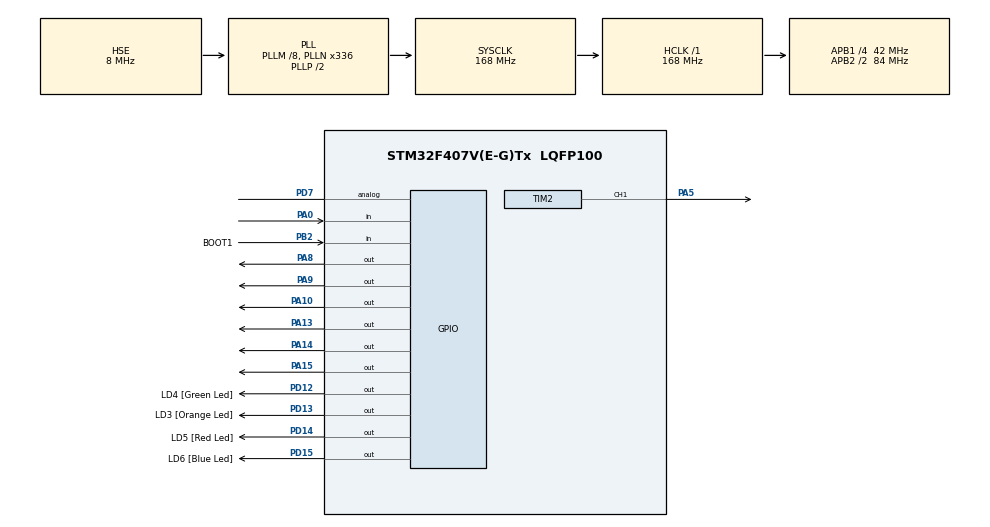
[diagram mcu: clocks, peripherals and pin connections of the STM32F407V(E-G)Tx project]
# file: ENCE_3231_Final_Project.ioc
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Mcu.Family=STM32F4
Mcu.Name=STM32F407V(E-G)Tx
Mcu.Package=LQFP100
NVIC.PriorityGroup=NVIC_PRIORITYGROUP_0
PA0-WKUP.Signal=GPIO_Input
PA10.Signal=GPIO_Output
PA13.Signal=GPIO_Output
PA14.Signal=GPIO_Output
PA15.Signal=GPIO_Output
PA5.Signal=S_TIM2_CH1_ETR
PA8.Signal=GPIO_Output
PA9.Signal=GPIO_Output
PB2.GPIO_Label=BOOT1
PB2.GPIO_Mode=GPIO_MODE_INPUT
PB2.GPIO_PuPd=GPIO_NOPULL
PB2.Signal=GPIO_Input
PC14-OSC32_IN.GPIO_Label=PC14-OSC32_IN
PC14-OSC32_IN.Mode=LSE-External-Oscillator
PC14-OSC32_IN.Signal=RCC_OSC32_IN
PC15-OSC32_OUT.GPIO_Label=PC15-OSC32_OUT
PC15-OSC32_OUT.Mode=LSE-External-Oscillator
PC15-OSC32_OUT.Signal=RCC_OSC32_OUT
PD12.GPIO_Label=LD4 [Green Led]
PD12.GPIO_PuPd=GPIO_NOPULL
PD12.GPIO_Speed=GPIO_SPEED_FREQ_LOW
PD12.Signal=GPIO_Output
PD13.GPIO_Label=LD3 [Orange Led]
PD13.GPIO_PuPd=GPIO_NOPULL
PD13.GPIO_Speed=GPIO_SPEED_FREQ_LOW
PD13.Signal=GPIO_Output
PD14.GPIO_Label=LD5 [Red Led]
PD14.GPIO_PuPd=GPIO_NOPULL
PD14.GPIO_Speed=GPIO_SPEED_FREQ_LOW
PD14.Signal=GPIO_Output
PD15.GPIO_Label=LD6 [Blue Led]
PD15.GPIO_PuPd=GPIO_NOPULL
PD15.GPIO_Speed=GPIO_SPEED_FREQ_LOW
PD15.Signal=GPIO_Output
PD7.Signal=GPIO_Analog
PE9.Signal=S_TIM1_CH1
PH0-OSC_IN.GPIO_Label=PH0-OSC_IN
PH0-OSC_IN.Mode=HSE-External-Oscillator
PH0-OSC_IN.Signal=RCC_OSC_IN
PH1-OSC_OUT.GPIO_Label=PH1-OSC_OUT
PH1-OSC_OUT.Mode=HSE-External-Oscillator
PH1-OSC_OUT.Signal=RCC_OSC_OUT
ProjectManager.HeapSize=0x200
ProjectManager.StackSize=0x400
ProjectManager.TargetToolchain=STM32CubeIDE
RCC.48MHZClocksFreq_Value=48000000
RCC.AHBFreq_Value=168000000
RCC.APB1CLKDivider=RCC_HCLK_DIV4
RCC.APB1Freq_Value=42000000
RCC.APB1TimFreq_Value=84000000
RCC.APB2CLKDivider=RCC_HCLK_DIV2
RCC.APB2Freq_Value=84000000
RCC.APB2TimFreq_Value=168000000
RCC.CortexFreq_Value=168000000
RCC.HCLKFreq_Value=168000000
RCC.HSE_VALUE=8000000
RCC.HSI_VALUE=16000000
RCC.PLLM=8
RCC.PLLN=336
RCC.PLLQ=7
RCC.PLLSourceVirtual=RCC_PLLSOURCE_HSE
RCC.SYSCLKFreq_VALUE=168000000
RCC.SYSCLKSource=RCC_SYSCLKSOURCE_PLLCLK
RCC.VCOOutputFreq_Value=336000000
SH.S_TIM1_CH1.0=TIM1_CH1
SH.S_TIM2_CH1_ETR.0=TIM2_CH1,PWM Generation1 CH1
TIM2.Channel-PWM\ Generation1\ CH1=TIM_CHANNEL_1
TIM2.Period=999
TIM2.Prescaler=71
TIM2.Pulse-PWM\ Generation1\ CH1=499
VP_TIM2_VS_ClockSourceINT.Mode=Internal
board=STM32F407G-DISC1

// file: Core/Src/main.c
/* USER CODE BEGIN Header */
/**
  ******************************************************************************
  * @file           : main.c
  * @brief          : Main program body
  ******************************************************************************
  * @attention
  *
  * Copyright (c) 2023 STMicroelectronics.
  * All rights reserved.
  *
  * This software is licensed under terms that can be found in the LICENSE file
  * in the root directory of this software component.
  * If no LICENSE file comes with this software, it is provided AS-IS.
  *
  ******************************************************************************
  */
/* USER CODE END Header */
#include "main.h"
#include <math.h>

/* USER CODE BEGIN Includes */
#include "lcd.c"
/* USER CODE END Includes */

/* USER CODE BEGIN PD */
# define PERIOD 999
# define MAXRPM 100
# define WHEELSIZE 20
/* USER CODE END PD */

TIM_HandleTypeDef htim2;

void SystemClock_Config(void);
static void MX_GPIO_Init(void);
static void MX_TIM2_Init(void);

int main(void)
{

  /* MCU Configuration--------------------------------------------------------*/

  /* Reset of all peripherals, Initializes the Flash interface and the Systick. */
  HAL_Init();

  /* Configure the system clock */
  SystemClock_Config();

  /* Initialize all configured peripherals */
  MX_GPIO_Init();
  MX_TIM2_Init();
  /* USER CODE BEGIN 2 */
  volatile int buttonFlag = 1;
  int analogValue = readAnalog();
  int convertedDC = convertDutyCycle(analogValue);
  /* Infinite loop */
  while (1)
  {
	  convertedDC = convertDutyCycle(500);
	  _HAL_TIM_SET_COMPARE(&htim2,TIM_CHANNEL_1, convertedDC);

	  if(buttonFlag = 1){
		  display("Speed", speedometer(convertedDC,WHEELSIZE));
	  }
	  if(buttonFlag = -1){
		  display("RPM", tachometer(convertedDC));
	  }

  }
}

void SystemClock_Config(void)
{
  RCC_OscInitTypeDef RCC_OscInitStruct = {0};
  RCC_ClkInitTypeDef RCC_ClkInitStruct = {0};

  /** Configure the main internal regulator output voltage
  */
  __HAL_RCC_PWR_CLK_ENABLE();
  __HAL_PWR_VOLTAGESCALING_CONFIG(PWR_REGULATOR_VOLTAGE_SCALE1);

  /** Initializes the RCC Oscillators according to the specified parameters
  * in the RCC_OscInitTypeDef structure.
  */
  RCC_OscInitStruct.OscillatorType = RCC_OSCILLATORTYPE_HSE;
  RCC_OscInitStruct.HSEState = RCC_HSE_ON;
  RCC_OscInitStruct.PLL.PLLState = RCC_PLL_ON;
  RCC_OscInitStruct.PLL.PLLSource = RCC_PLLSOURCE_HSE;
  RCC_OscInitStruct.PLL.PLLM = 8;
  RCC_OscInitStruct.PLL.PLLN = 336;
  RCC_OscInitStruct.PLL.PLLP = RCC_PLLP_DIV2;
  RCC_OscInitStruct.PLL.PLLQ = 7;
  if (HAL_RCC_OscConfig(&RCC_OscInitStruct) != HAL_OK)
  {
    Error_Handler();
  }

  /** Initializes the CPU, AHB and APB buses clocks
  */
  RCC_ClkInitStruct.ClockType = RCC_CLOCKTYPE_HCLK|RCC_CLOCKTYPE_SYSCLK
                              |RCC_CLOCKTYPE_PCLK1|RCC_CLOCKTYPE_PCLK2;
  RCC_ClkInitStruct.SYSCLKSource = RCC_SYSCLKSOURCE_PLLCLK;
  RCC_ClkInitStruct.AHBCLKDivider = RCC_SYSCLK_DIV1;
  RCC_ClkInitStruct.APB1CLKDivider = RCC_HCLK_DIV4;
  RCC_ClkInitStruct.APB2CLKDivider = RCC_HCLK_DIV2;

  if (HAL_RCC_ClockConfig(&RCC_ClkInitStruct, FLASH_LATENCY_5) != HAL_OK)
  {
    Error_Handler();
  }
}

static void MX_TIM2_Init(void)
{

  TIM_ClockConfigTypeDef sClockSourceConfig = {0};
  TIM_MasterConfigTypeDef sMasterConfig = {0};
  TIM_OC_InitTypeDef sConfigOC = {0};

  htim2.Instance = TIM2;
  htim2.Init.Prescaler = 71;
  htim2.Init.CounterMode = TIM_COUNTERMODE_UP;
  htim2.Init.Period = 999;
  htim2.Init.ClockDivision = TIM_CLOCKDIVISION_DIV1;
  htim2.Init.AutoReloadPreload = TIM_AUTORELOAD_PRELOAD_DISABLE;
  if (HAL_TIM_Base_Init(&htim2) != HAL_OK)
  {
    Error_Handler();
  }
  sClockSourceConfig.ClockSource = TIM_CLOCKSOURCE_INTERNAL;
  if (HAL_TIM_ConfigClockSource(&htim2, &sClockSourceConfig) != HAL_OK)
  {
    Error_Handler();
  }
  if (HAL_TIM_PWM_Init(&htim2) != HAL_OK)
  {
    Error_Handler();
  }
  sMasterConfig.MasterOutputTrigger = TIM_TRGO_RESET;
  sMasterConfig.MasterSlaveMode = TIM_MASTERSLAVEMODE_DISABLE;
  if (HAL_TIMEx_MasterConfigSynchronization(&htim2, &sMasterConfig) != HAL_OK)
  {
    Error_Handler();
  }
  sConfigOC.OCMode = TIM_OCMODE_PWM1;
  sConfigOC.Pulse = 499;
  sConfigOC.OCPolarity = TIM_OCPOLARITY_HIGH;
  sConfigOC.OCFastMode = TIM_OCFAST_DISABLE;
  if (HAL_TIM_PWM_ConfigChannel(&htim2, &sConfigOC, TIM_CHANNEL_1) != HAL_OK)
  {
    Error_Handler();
  }
  HAL_TIM_MspPostInit(&htim2);

}

static void MX_GPIO_Init(void)
{
  GPIO_InitTypeDef GPIO_InitStruct = {0};

  /* GPIO Ports Clock Enable */
  __HAL_RCC_GPIOC_CLK_ENABLE();
  __HAL_RCC_GPIOH_CLK_ENABLE();
  __HAL_RCC_GPIOA_CLK_ENABLE();
  __HAL_RCC_GPIOB_CLK_ENABLE();
  __HAL_RCC_GPIOE_CLK_ENABLE();
  __HAL_RCC_GPIOD_CLK_ENABLE();

  /*Configure GPIO pin Output Level */
  HAL_GPIO_WritePin(GPIOD, LD4_Pin|LD3_Pin|LD5_Pin|LD6_Pin, GPIO_PIN_RESET);

  /*Configure GPIO pin Output Level */
  HAL_GPIO_WritePin(GPIOA, GPIO_PIN_8|GPIO_PIN_9|GPIO_PIN_10|GPIO_PIN_13
                          |GPIO_PIN_14|GPIO_PIN_15, GPIO_PIN_RESET);

  /*Configure GPIO pin : B1_Pin */
  GPIO_InitStruct.Pin = B1_Pin;
  GPIO_InitStruct.Mode = GPIO_MODE_EVT_RISING;
  GPIO_InitStruct.Pull = GPIO_NOPULL;
  HAL_GPIO_Init(B1_GPIO_Port, &GPIO_InitStruct);

  /*Configure GPIO pin : BOOT1_Pin */
  GPIO_InitStruct.Pin = BOOT1_Pin;
  GPIO_InitStruct.Mode = GPIO_MODE_INPUT;
  GPIO_InitStruct.Pull = GPIO_NOPULL;
  HAL_GPIO_Init(BOOT1_GPIO_Port, &GPIO_InitStruct);

  /*Configure GPIO pin : PE9 */
  GPIO_InitStruct.Pin = GPIO_PIN_9;
  GPIO_InitStruct.Mode = GPIO_MODE_AF_PP;
  GPIO_InitStruct.Pull = GPIO_NOPULL;
  GPIO_InitStruct.Speed = GPIO_SPEED_FREQ_LOW;
  GPIO_InitStruct.Alternate = GPIO_AF1_TIM1;
  HAL_GPIO_Init(GPIOE, &GPIO_InitStruct);

  /*Configure GPIO pins : LD4_Pin LD3_Pin LD5_Pin LD6_Pin */
  GPIO_InitStruct.Pin = LD4_Pin|LD3_Pin|LD5_Pin|LD6_Pin;
  GPIO_InitStruct.Mode = GPIO_MODE_OUTPUT_PP;
  GPIO_InitStruct.Pull = GPIO_NOPULL;
  GPIO_InitStruct.Speed = GPIO_SPEED_FREQ_LOW;
  HAL_GPIO_Init(GPIOD, &GPIO_InitStruct);

  /*Configure GPIO pins : PA8 PA9 PA10 PA13
                           PA14 PA15 */
  GPIO_InitStruct.Pin = GPIO_PIN_8|GPIO_PIN_9|GPIO_PIN_10|GPIO_PIN_13
                          |GPIO_PIN_14|GPIO_PIN_15;
  GPIO_InitStruct.Mode = GPIO_MODE_OUTPUT_PP;
  GPIO_InitStruct.Pull = GPIO_NOPULL;
  GPIO_InitStruct.Speed = GPIO_SPEED_FREQ_LOW;
  HAL_GPIO_Init(GPIOA, &GPIO_InitStruct);

  /*Configure GPIO pin : PD7 */
  GPIO_InitStruct.Pin = GPIO_PIN_7;
  GPIO_InitStruct.Mode = GPIO_MODE_ANALOG;
  GPIO_InitStruct.Pull = GPIO_NOPULL;
  HAL_GPIO_Init(GPIOD, &GPIO_InitStruct);
  /* Configure GPIO pin : UserButton_Pin */
  GPIO_InitStruct.Pin = GPIO_PIN_0;
  GPIO_InitStruct.Mode = GPIO_MODE_INPUT;
  GPIO_InitStruct.Pull = GPIO_NOPULL;
  HAL_GPIO_Init(GPIOA, &GPIO_InitStruct);
  /* Configure GPIO pin interrupt */
  GPIO_InitStruct.Mode = GPIO_MODE_IT_FALLING; // Set interrupt mode and trigger on falling edge
  HAL_GPIO_Init(UserButton_GPIO_Port, &GPIO_InitStruct);

  /* Enable and set EXTI line interrupt to the corresponding GPIO pin */
  HAL_NVIC_SetPriority(EXTI0_IRQn, 0, 0);
  HAL_NVIC_EnableIRQ(EXTI0_IRQn);

}

/* USER CODE BEGIN 4 */
void EXTI0_IRQHandler(void)
{
    // Handle the interrupt here

    // Toggle an LED
   buttonFlag *= -1;

    // Clear the interrupt flag
    HAL_GPIO_EXTI_IRQHandler(GPIO_PIN_0);
}
/* USER CODE END 4 */

void Error_Handler(void)
{
  __disable_irq();
  while (1)
  {
  }
}
int readAnalog(){
	int analogValue = HAL_GPIO_ReadPin(GPIOD, GPIO_PIN_7);
	return analogValue;
}

int convertDutyCycle(int GPIO_Input){
	int dutyCycle = GPIO_Input*1024/PERIOD;
	return dutyCycle;
}
void display(char message[], int value){
	// Lcd_PortType ports[] = { D4_GPIO_Port, D5_GPIO_Port, D6_GPIO_Port, D7_GPIO_Port };
	    Lcd_PortType ports[] = { GPIOA, GPIOA, GPIOA, GPIOA };
	    // Lcd_PinType pins[] = {D4_Pin, D5_Pin, D6_Pin, D7_Pin};
	    Lcd_PinType pins[] = {GPIO_PIN_10, GPIO_PIN_13, GPIO_PIN_14, GPIO_PIN_15};
	    Lcd_HandleTypeDef lcd;
	    // Lcd_create(ports, pins, RS_GPIO_Port, RS_Pin, EN_GPIO_Port, EN_Pin, LCD_4_BIT_MODE);
	    lcd = Lcd_create(ports, pins, GPIOA, GPIO_PIN_8, GPIOA, GPIO_PIN_9, LCD_4_BIT_MODE);
	    Lcd_cursor(&lcd, 0,1);
	    Lcd_string(&lcd, message);
	    Lcd_cursor(&lcd, 1,7);
	    Lcd_int(&lcd, value);
	    HAL_Delay (1000);
}
int speedometer(int converted, int wheelSize){
	int rpm;
	int circ;
	int speed;
	rpm = (int)converted*MAXRPM/100;
	circ = 3.14159*wheelSize;
	speed = circ*rpm;
	return speed;

}
int tachometer(int converted){
	int rpm;
	rpm = (int)converted*MAXRPM/100;
	return rpm;
}
